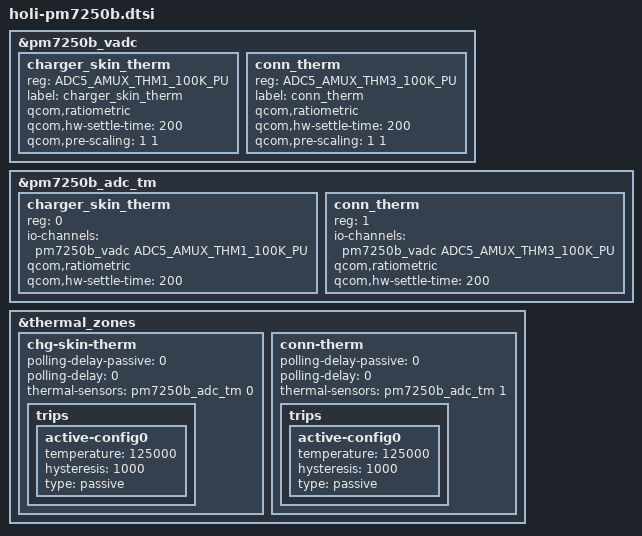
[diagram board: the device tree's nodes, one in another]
#include <dt-bindings/thermal/thermal_qti.h>
#include "pm7250b.dtsi"

&pm7250b_vadc {
	charger_skin_therm {
		reg = <ADC5_AMUX_THM1_100K_PU>;
		label = "charger_skin_therm";
		qcom,ratiometric;
		qcom,hw-settle-time = <200>;
		qcom,pre-scaling = <1 1>;
	};

	conn_therm {
		reg = <ADC5_AMUX_THM3_100K_PU>;
		label = "conn_therm";
		qcom,ratiometric;
		qcom,hw-settle-time = <200>;
		qcom,pre-scaling = <1 1>;
	};
};

&pm7250b_adc_tm {
	/* Channel nodes */
	charger_skin_therm {
		reg = <0>;
		io-channels = <&pm7250b_vadc ADC5_AMUX_THM1_100K_PU>;
		qcom,ratiometric;
		qcom,hw-settle-time = <200>;
	};

	conn_therm {
		reg = <1>;
		io-channels = <&pm7250b_vadc ADC5_AMUX_THM3_100K_PU>;
		qcom,ratiometric;
		qcom,hw-settle-time = <200>;
	};
};

&thermal_zones {
	chg-skin-therm {
		polling-delay-passive = <0>;
		polling-delay = <0>;
		thermal-sensors = <&pm7250b_adc_tm 0>;
		trips {
			active-config0 {
				temperature = <125000>;
				hysteresis = <1000>;
				type = "passive";
			};
		};
	};

	conn-therm {
		polling-delay-passive = <0>;
		polling-delay = <0>;
		thermal-sensors = <&pm7250b_adc_tm 1>;
		trips {
			active-config0 {
				temperature = <125000>;
				hysteresis = <1000>;
				type = "passive";
			};
		};
	};
};
